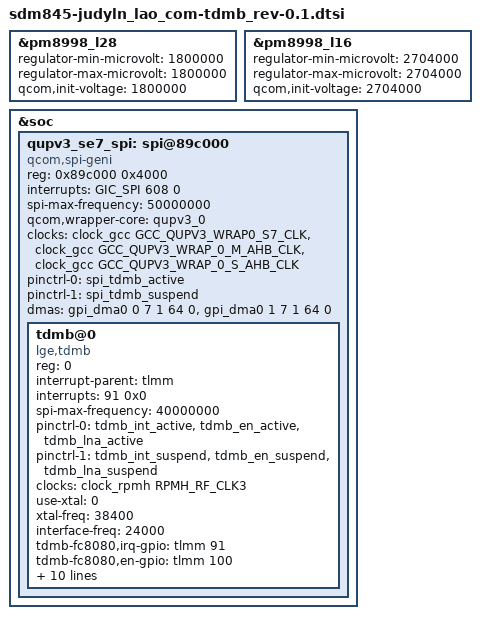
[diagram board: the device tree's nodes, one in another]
/* Copyright (c) 2017, The Linux Foundation. All rights reserved.
 *
 * This program is free software; you can redistribute it and/or modify
 * it under the terms of the GNU General Public License version 2 and
 * only version 2 as published by the Free Software Foundation.
 *
 * This program is distributed in the hope that it will be useful,
 * but WITHOUT ANY WARRANTY; without even the implied warranty of
 * MERCHANTABILITY or FITNESS FOR A PARTICULAR PURPOSE.  See the
 * GNU General Public License for more details.
 */

&pm8998_l28 {
	regulator-min-microvolt = <1800000>;
	regulator-max-microvolt = <1800000>;
	qcom,init-voltage = <1800000>;
	status = "ok";
};

&pm8998_l16 {
	regulator-min-microvolt = <2704000>;
	regulator-max-microvolt = <2704000>;
	qcom,init-voltage = <2704000>;
	status = "ok";
};


&soc {
		qupv3_se7_spi: spi@89c000 {	// [Modified] QUP_BASE address for BLSP# QUP# (ref. AP datasheet, This model use BLSP-1 QUP7)
			/* [S][Modified] Ref. kernel/msm-4.9/arch/arm64/boot/dts/qcom/sdm845-qupv3.dtsi */
			compatible = "qcom,spi-geni"; // [Fixed] Should be "qcom,spi-geni (qup-v3)".

			#address-cells = <1>;
			#size-cells = <0>;

			reg-names = "se_phys";
			reg = <0x89c000 0x4000>;

			interrupts = <GIC_SPI 608 0>;

			spi-max-frequency = <50000000>;
			qcom,wrapper-core = <&qupv3_0>;

			clock-names = "se-clk", "m-ahb", "s-ahb";
			clocks = <&clock_gcc GCC_QUPV3_WRAP0_S7_CLK>,
				<&clock_gcc GCC_QUPV3_WRAP_0_M_AHB_CLK>,
				<&clock_gcc GCC_QUPV3_WRAP_0_S_AHB_CLK>;
			/* [E][Modified] Ref. kernel/msm-4.9/arch/arm64/boot/dts/qcom/sdm845-qupv3.dtsi */

			// [Fixed] Must contain "default" and "sleep" if pinctrl is to be used. Keep the same names.
			pinctrl-names = "default", "sleep";
			/* [Fixed] List of phandles, each pointing at a pin configuration node within a pin controller.
				The list of names to assign states, List entry 0 defines the name for integer state ID 0... */
			pinctrl-0 = <&spi_tdmb_active>;
			pinctrl-1 = <&spi_tdmb_suspend>;

			dmas = <&gpi_dma0 0 7 1 64 0>, <&gpi_dma0 1 7 1 64 0>;
			dma-names = "tx", "rx";
			status = "ok";
		};
};


&qupv3_se7_spi {
	tdmb@0 {
		compatible = "lge,tdmb"; // [Fixed] Should be "lge,tdmb".
		reg = <0>;
		interrupt-parent = <&tlmm>;  // [Fixed] tlmm is the parent
		interrupts = <91 0x0>; // [Modified] Set tdmb_int GPIO, first # is gpio #, second flag keep it 0.

		// [Fixed] Specifies maximum SPI clock frequency of DMB chipset(38.4 MHz). (ref. FC8080 datasheet)
		spi-max-frequency = <40000000>;

	/* [2. GPIO Information]
	*  1) tdmb_int      (DMB_INT)                     : GPIO #91
	*  2) tdmb_ctrl     (DMB_EN)                      : GPIO #100
	*  3) tdmb_ant      (DMB_FM_SW)                   : NA (Not control)
	*  4) tdmb_lna_ctrl (DMB_GAIN_CTRL)               : GPIO #129
	*  5) tdmb_lna_en   (DMB_LNA_EN)                  : GPIO #128
	*/
		/* [Fixed] The list of names to assign states, List entry 0,1,2... define the name for integer state ID 0,1,2...
			- tdmb_pin_active : set to pinctrl-0 list (set to active)
			- tdmb_pin_sleep : set to pinctrl-1 list (set to sleep)
		*/
		pinctrl-names = "tdmb_pin_active", "tdmb_pin_sleep";

		/* [Modified] The pin cofig lists can be for control pin.
			- pinctrl-0 : active state
			- pinctrl-1 : active sleep(suspend)
			The pin config lists shall be defined in the "(model)-pinctrl.dtsi" file
			The control pins lists are interrupt(tdmb_int), enable(tdmb_en), FM/DMB antenna swtiching(tdmb_ant), LNA gain control & enable(tdmb_lna)
			Additional items may vary depending on model schematic.
		*/
		pinctrl-0 = <&tdmb_int_active>, <&tdmb_en_active>, <&tdmb_lna_active>; 
		pinctrl-1 = <&tdmb_int_suspend>, <&tdmb_en_suspend>, <&tdmb_lna_suspend>; 

		/* [Modified] when using clock buffer,
			 you should check which clock buffer used for dmb device */
		clock-names = "tdmb_xo";
		clocks = <&clock_rpmh RPMH_RF_CLK3>;

		/* [Modified] set hw configure here
			when use pmic clk buffer, change use-xtal to 0
			and set xtal-freq(DMB Chipset Core clk), interface-freq(SPI interface clk) inter value in kHz. */
		use-xtal = <0>;
		xtal-freq = <38400>;
		interface-freq = <24000>;

		/* [Modified] Set DMB-EN, DMB-INT GPIO
			tlmm is the parent, second # is gpio #, third flag keep it 0. */
		tdmb-fc8080,irq-gpio = <&tlmm 91 0x00>;
		tdmb-fc8080,en-gpio = <&tlmm 100 0x00>;

		/* [Modified] when use ant switching, change use-ant-sw to 1, 
			and set ant active mode (high(1) or low(0)), ant-gpio.
			ant-apio should be tdmb_ant's Gpio number */

	/* [3. RF Switch Information]
	*  1) FM/DMB Switch                               : NA (Not control)
	*  2) TDMB ANT connected to port1 (High) and FM_ANT connected to port2 (Low), so active mode is high
	*/

		use-ant-sw = <0>;
		//ant-active-mode = <1>;
		//tdmb-fc8080,ant-gpio = <&tlmm 22 0x00>;


	/* [5. Power Supply Description Information]
	*  1) RFSW LDO     (pm8998_l16)                    : V2.7, Not always power, power on/off control need
	*  2) DMB LDO      (pm8998_l28)                    : V1.8, Not always power, power on/off control need
	*  3) LNA LDO      (pm8998_l16)                    : V2.7, Not always power, power on/off control need
	*/

		/* [Modified] When use ldo for RFSW, change ctrl-rfsw-ldo to 1, and dmb_rfsw-supply set the appropriate chipset & power function such as <&pm8953_l10>
		   If no use case, change ctrl-rfsw-ldo to 0, and dmb_rfsw-supply set such as <&chipset#_l??>*/
		ctrl-rfsw-ldo = <0>;
		//rfsw_ldo-supply = <&chipset#_l??>;

		/* [Modified] when use ldo for LDO_IN, change ctrl-dmb-ldo to 1, and dmb_ldo-supply set the appropriate chipset & power function such as <&pm8953_l10>
		   If no use case, change ctrl-dmb-ldo to 0, and dmb_ldo-supply set such as <&chipset#_l??>*/
		ctrl-dmb-ldo = <1>;
		dmb_ldo-supply = <&pm8998_l28>;

		/* [Modified] when use ldo for LNA(U1800), change ctrl-lna-ldo to 1, and lna_ldo-supply set the appropriate chipset & power function such as <&pm8953_l10>
		   If no use case, change ctrl-lna-ldo to 0, and lna_ldo-supply set such as <&chipset#_l??>*/
		ctrl-lna-ldo = <1>;
		lna_ldo-supply = <&pm8998_l16>;

		/* [Modified] when use LNA, chage use-lna-ctrl to 1, and lna-ctrl-gpio set the DMB_GAIN_CTRL's gpio number
		   If no use case, change use-lna-ctrl to 0, and lna-ctrl-gpio set such as <&tlmm ?? 0x00>*/
		use-lna-ctrl = <1>;
		tdmb-fc8080,lna-ctrl-gpio = <&tlmm 129 0x00>;

		/* [Modified] when use LNA EN, chage use-lna-en to 1, and lna-en-gpio set the DMB_LNA_EN's gpio number
		   If no use case, change use-lna-en to 0, and lna-en-gpio set such as <&tlmm ?? 0x00>*/
		use-lna-en = <1>;
		tdmb-fc8080,lna-en-gpio = <&tlmm 128 0x00>;
	};
};
